# G32R501 register map
Vendor: Geehy Semiconductor Co., Ltd.; Series: G32R5; File version: 1.0
CPU: CM55 r0p1, little endian, MPU, FPU, double-precision FPU, DSP, VTOR, 4 interrupt priority bits
Registers are 32-bit, read-write, reset 0x0 unless marked. A register's access mark holds for its fields unless they carry their own. Offsets are from the block's base; [hi:lo] are bit positions.

## FSI_TX — Fast Serial Interface
Base 0x50100C00
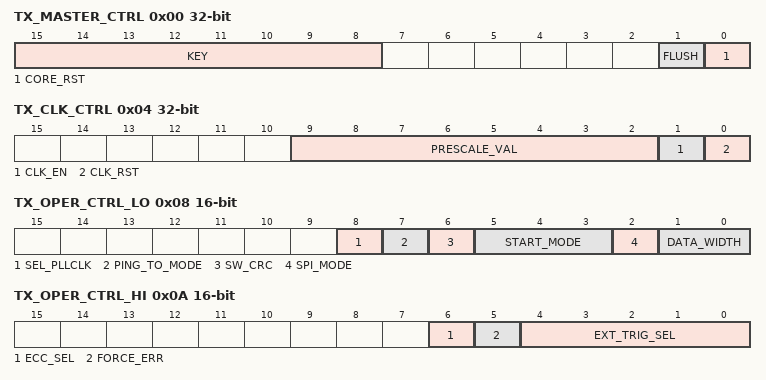
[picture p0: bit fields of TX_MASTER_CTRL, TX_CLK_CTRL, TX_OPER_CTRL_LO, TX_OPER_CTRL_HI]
0x00 TX_MASTER_CTRL access per field — Transmit master control register
  [15:8] KEY wo — Write Key
  [1] FLUSH rw — Flush Operation Start bit
  [0] CORE_RST rw — Transmitter Main Core Reset bit
0x04 TX_CLK_CTRL — Transmit clock control register
  [9:2] PRESCALE_VAL — Clock Divider Prescale Value
  [1] CLK_EN — Clock Divider Enable bit
  [0] CLK_RST — Clock Divider Reset bit
0x08 TX_OPER_CTRL_LO 16-bit — Transmit operation control register low
  [8] SEL_PLLCLK — Input Clock Select bit
  [7] PING_TO_MODE — Ping Counter Reset Mode Select bit
  [6] SW_CRC — CRC Source Select bit
  [5:3] START_MODE — Transmission Start Mode Select bit
  [2] SPI_MODE — SPI Mode Select bit
  [1:0] DATA_WIDTH — Transmit Data Width Select bits
0x0A TX_OPER_CTRL_HI 16-bit — Transmit operation control register high
  [6] ECC_SEL — ECC Data Width Select bit
  [5] FORCE_ERR — Error Frame Force bit
  [4:0] EXT_TRIG_SEL — External Trigger Select bit
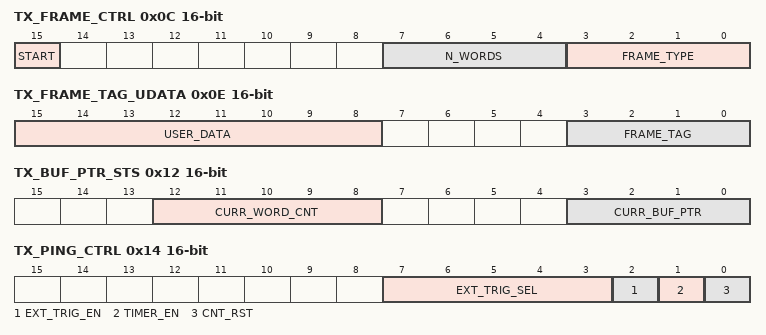
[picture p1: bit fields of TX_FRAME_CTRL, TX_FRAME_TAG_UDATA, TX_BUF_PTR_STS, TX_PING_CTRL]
0x0C TX_FRAME_CTRL 16-bit — Transmit frame control register
  [15] START — Start Transmission bit
  [7:4] N_WORDS — Number of Words to be Transmitted
  [3:0] FRAME_TYPE — Transmit Frame Type
0x0E TX_FRAME_TAG_UDATA 16-bit — Transmit frame tag and user data register
  [15:8] USER_DATA — User Data bits
  [3:0] FRAME_TAG — Frame tag bits
0x10 TX_BUF_PTR_LOAD 16-bit — Transmit buffer pointer control load register
  [3:0] BUF_PTR_LOAD — Buffer Pointer Load bits
0x12 TX_BUF_PTR_STS 16-bit ro — Transmit buffer pointer control status register
  [12:8] CURR_WORD_CNT — Words Remaining in the transmit buffer
  [3:0] CURR_BUF_PTR — Current Buffer Pointer Index
0x14 TX_PING_CTRL 16-bit — Transmit ping control register
  [7:3] EXT_TRIG_SEL — External Trigger Select bits
  [2] EXT_TRIG_EN — External Trigger Enable bit
  [1] TIMER_EN — Ping Timer Enable bit
  [0] CNT_RST — Ping Counter Reset bit
0x16 TX_PING_TAG 16-bit — Transmit ping tag register
  [3:0] TAG — Ping Frame Tag
0x18 TX_PING_TO_REF — Transmit ping timeout counter reference
  [31:0] TO_REF — Ping Timer Reference Value
0x1C TX_PING_TO_CNT ro — Transmit ping timeout current count
  [31:0] TO_CNT — Ping Timer Counter Value
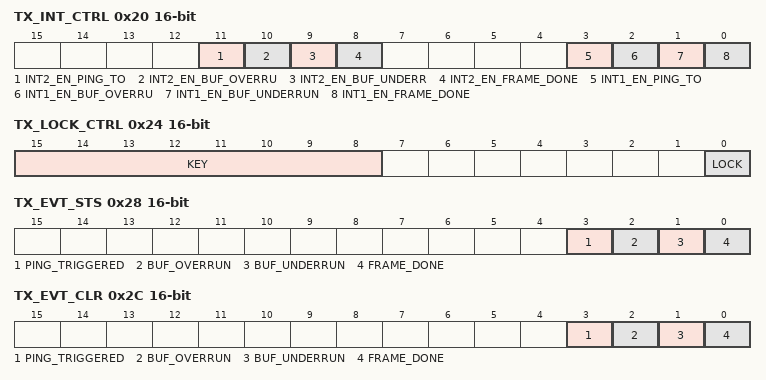
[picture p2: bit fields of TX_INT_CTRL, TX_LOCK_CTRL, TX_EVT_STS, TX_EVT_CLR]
0x20 TX_INT_CTRL 16-bit — Transmit interrupt event control register
  [11] INT2_EN_PING_TO — Enable PING Timer Interrupt to INT2
  [10] INT2_EN_BUF_OVERRU — Enable Buffer Overrun Interrupt to INT2
  [9] INT2_EN_BUF_UNDERR — Enable Buffer Underrun Interrupt to INT2
  [8] INT2_EN_FRAME_DONE — Enable Frame Done interrupt to INT2
  [3] INT1_EN_PING_TO — Enable Ping Timer Interrupt to INT1
  [2] INT1_EN_BUF_OVERRU — Enable Buffer Overrun Interrupt to INT1
  [1] INT1_EN_BUF_UNDERRUN — Enable Buffer Underrun Interrupt to INT1
  [0] INT1_EN_FRAME_DONE — Enable Frame Done interrupt to INT1
0x22 TX_DMA_CTRL 16-bit — Transmit DMA event control register
  [0] DMA_EVT_EN — DMA Event Enable bit
0x24 TX_LOCK_CTRL 16-bit access per field — Transmit lock control register
  [15:8] KEY wo — Write Key
  [0] LOCK rw — Control Register Lock Enable bit
0x28 TX_EVT_STS 16-bit ro — Transmit event and error status flag register
  [3] PING_TRIGGERED — Ping Frame Triggered Flag Bit
  [2] BUF_OVERRUN — Buffer Overrun Flag Bit
  [1] BUF_UNDERRUN — Buffer Underrun Flag Bit
  [0] FRAME_DONE — Frame Done Flag Bit
0x2C TX_EVT_CLR 16-bit wo — Transmit event and error clear register
  [3] PING_TRIGGERED — Ping Frame Triggered Flag Clear bit
  [2] BUF_OVERRUN — Buffer Overrun Flag Clear bit
  [1] BUF_UNDERRUN — Buffer Underrun Flag Clear bit
  [0] FRAME_DONE — Frame Done Flag Clear bit
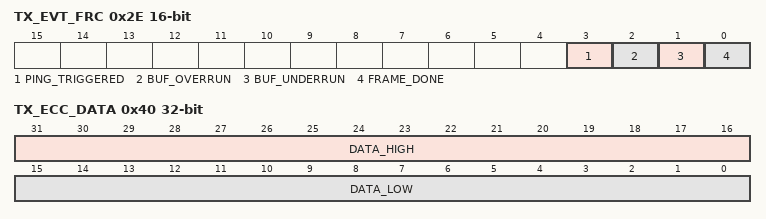
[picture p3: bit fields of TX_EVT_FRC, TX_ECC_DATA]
0x2E TX_EVT_FRC 16-bit wo — Transmit event and error flag force register
  [3] PING_TRIGGERED — Ping Frame Triggered Flag Force bit
  [2] BUF_OVERRUN — Buffer Overrun Flag Force bit
  [1] BUF_UNDERRUN — Buffer Underrun Flag Force bit
  [0] FRAME_DONE — Frame Done Flag Force bit
0x30 TX_USER_CRC 16-bit — Transmit user-defined CRC register
  [7:0] USER_CRC — User-defined CRC
0x40 TX_ECC_DATA — Transmit ECC data register
  [31:16] DATA_HIGH — Upper 16 bits of ECC Data
  [15:0] DATA_LOW — Lower 16 bits of ECC Data
0x44 TX_ECC_VAL 16-bit ro reset 0xC — Transmit ECC value register
  [6:0] ECC_VAL — Computed ECC Value
0x80 TX_BUF_BASE 16-bit — Base address for transmit buffer
  [15:0] BASE_ADDRESS — Transmit Data Buffer Base Address
